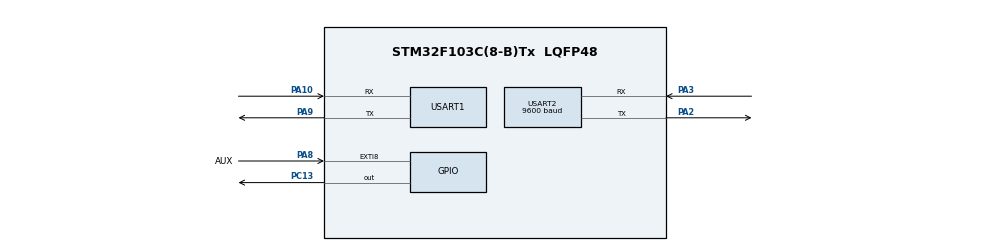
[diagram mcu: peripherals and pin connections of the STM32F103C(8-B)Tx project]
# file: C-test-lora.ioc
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Dma.Request0=USART2_RX
Dma.Request1=USART2_TX
Dma.USART2_RX.0.Direction=DMA_PERIPH_TO_MEMORY
Dma.USART2_RX.0.Instance=DMA1_Channel6
Dma.USART2_RX.0.MemDataAlignment=DMA_MDATAALIGN_BYTE
Dma.USART2_RX.0.MemInc=DMA_MINC_ENABLE
Dma.USART2_RX.0.Mode=DMA_NORMAL
Dma.USART2_RX.0.PeriphDataAlignment=DMA_PDATAALIGN_BYTE
Dma.USART2_RX.0.PeriphInc=DMA_PINC_DISABLE
Dma.USART2_RX.0.Priority=DMA_PRIORITY_LOW
Dma.USART2_TX.1.Direction=DMA_MEMORY_TO_PERIPH
Dma.USART2_TX.1.Instance=DMA1_Channel7
Dma.USART2_TX.1.MemDataAlignment=DMA_MDATAALIGN_BYTE
Dma.USART2_TX.1.MemInc=DMA_MINC_ENABLE
Dma.USART2_TX.1.Mode=DMA_NORMAL
Dma.USART2_TX.1.PeriphDataAlignment=DMA_PDATAALIGN_BYTE
Dma.USART2_TX.1.PeriphInc=DMA_PINC_DISABLE
Dma.USART2_TX.1.Priority=DMA_PRIORITY_LOW
FREERTOS.CountingSemaphores01=loraRxSem,10,Dynamic,NULL,0
FREERTOS.Queues01=loraErrQueue,16,lora_state_t,0,Dynamic,NULL,NULL;cmdQueue,16,uint8_t,0,Dynamic,NULL,NULL
FREERTOS.Tasks01=defaultTask,24,128,StartDefaultTask,Default,NULL,Dynamic,NULL,NULL;mainCmdTask,8,128,StartTaskMainCmd,As external,NULL,Dynamic,NULL,NULL
FREERTOS.configTOTAL_HEAP_SIZE=5000
Mcu.Family=STM32F1
Mcu.Name=STM32F103C(8-B)Tx
Mcu.Package=LQFP48
NVIC.DMA1_Channel6_IRQn=true\:5\:0\:false\:false\:true\:true\:false\:true\:true
NVIC.DMA1_Channel7_IRQn=true\:5\:0\:false\:false\:true\:true\:false\:true\:true
NVIC.EXTI9_5_IRQn=true\:5\:0\:false\:false\:true\:true\:true\:true\:true
NVIC.PriorityGroup=NVIC_PRIORITYGROUP_4
NVIC.TIM4_IRQn=true\:15\:0\:false\:false\:true\:false\:false\:true\:true
NVIC.TimeBase=TIM4_IRQn
NVIC.TimeBaseIP=TIM4
NVIC.USART2_IRQn=true\:5\:0\:false\:false\:true\:true\:false\:true\:true
PA10.Mode=Asynchronous
PA10.Signal=USART1_RX
PA13.Mode=Serial_Wire
PA13.Signal=SYS_JTMS-SWDIO
PA14.Mode=Serial_Wire
PA14.Signal=SYS_JTCK-SWCLK
PA2.Mode=Asynchronous
PA2.Signal=USART2_TX
PA3.Mode=Asynchronous
PA3.Signal=USART2_RX
PA8.GPIO_Label=AUX
PA8.GPIO_ModeDefaultEXTI=GPIO_MODE_IT_RISING
PA8.GPIO_PuPd=GPIO_PULLDOWN
PA8.Signal=GPXTI8
PA9.Mode=Asynchronous
PA9.Signal=USART1_TX
PC13-TAMPER-RTC.Signal=GPIO_Output
PD0-OSC_IN.Mode=HSE-External-Oscillator
PD0-OSC_IN.Signal=RCC_OSC_IN
PD1-OSC_OUT.Mode=HSE-External-Oscillator
PD1-OSC_OUT.Signal=RCC_OSC_OUT
ProjectManager.HeapSize=0x200
ProjectManager.StackSize=0x400
ProjectManager.TargetToolchain=STM32CubeIDE
RCC.APB1Freq_Value=8000000
RCC.APB2Freq_Value=8000000
USART1.VirtualMode=VM_ASYNC
USART2.BaudRate=9600
USART2.VirtualMode=VM_ASYNC
VP_FREERTOS_VS_CMSIS_V2.Mode=CMSIS_V2
VP_SYS_VS_tim4.Mode=TIM4
board=custom

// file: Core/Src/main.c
/* USER CODE BEGIN Header */
/**
  ******************************************************************************
  * @file           : main.c
  * @brief          : Main program body
  ******************************************************************************
  * @attention
  *
  * Copyright (c) 2026 STMicroelectronics.
  * All rights reserved.
  *
  * This software is licensed under terms that can be found in the LICENSE file
  * in the root directory of this software component.
  * If no LICENSE file comes with this software, it is provided AS-IS.
  *
  ******************************************************************************
  */
/* USER CODE END Header */
#include "main.h"
#include "cmsis_os.h"
#include "dma.h"
#include "usart.h"
#include "gpio.h"

/* USER CODE BEGIN Includes */
#include "lora.h"
/* USER CODE END Includes */

void SystemClock_Config(void);
void MX_FREERTOS_Init(void);

int main(void)
{

  /* MCU Configuration--------------------------------------------------------*/

  /* Reset of all peripherals, Initializes the Flash interface and the Systick. */
  HAL_Init();

  /* Configure the system clock */
  SystemClock_Config();

  /* Initialize all configured peripherals */
  MX_GPIO_Init();
  MX_DMA_Init();
  MX_USART2_UART_Init();
  MX_USART1_UART_Init();
  /* USER CODE BEGIN 2 */
  /* 板载 LED：多数 F103 小板是低电平点亮，这里拉高只是先把状态定下来 */
  HAL_GPIO_WritePin(GPIOC, GPIO_PIN_13, GPIO_PIN_SET);

  /* 配置 LoRa：进 AT -> 设参数 -> 复位 -> 挂接收，全程阻塞约 1.5 秒。
     必须在调度器启动前做，因为 lora_init 里用的是 HAL_Delay，不依赖 RTOS。 */
  lora_init();

  /* 自检：给对端发 5 字节，另一块板的串口助手应原样收到 "shabi" */
  lora_send((uint8_t *)"shabi", 5);

  /* USER CODE END 2 */

  /* Init scheduler */
  osKernelInitialize();  /* Call init function for freertos objects (in cmsis_os2.c) */
  MX_FREERTOS_Init();

  /* Start scheduler */
  osKernelStart();

  /* We should never get here as control is now taken by the scheduler */

  /* Infinite loop */
  while (1)
  {

  }
}

void SystemClock_Config(void)
{
  RCC_OscInitTypeDef RCC_OscInitStruct = {0};
  RCC_ClkInitTypeDef RCC_ClkInitStruct = {0};

  /** Initializes the RCC Oscillators according to the specified parameters
  * in the RCC_OscInitTypeDef structure.
  */
  RCC_OscInitStruct.OscillatorType = RCC_OSCILLATORTYPE_HSI;
  RCC_OscInitStruct.HSIState = RCC_HSI_ON;
  RCC_OscInitStruct.HSICalibrationValue = RCC_HSICALIBRATION_DEFAULT;
  RCC_OscInitStruct.PLL.PLLState = RCC_PLL_NONE;
  if (HAL_RCC_OscConfig(&RCC_OscInitStruct) != HAL_OK)
  {
    Error_Handler();
  }

  /** Initializes the CPU, AHB and APB buses clocks
  */
  RCC_ClkInitStruct.ClockType = RCC_CLOCKTYPE_HCLK|RCC_CLOCKTYPE_SYSCLK
                              |RCC_CLOCKTYPE_PCLK1|RCC_CLOCKTYPE_PCLK2;
  RCC_ClkInitStruct.SYSCLKSource = RCC_SYSCLKSOURCE_HSI;
  RCC_ClkInitStruct.AHBCLKDivider = RCC_SYSCLK_DIV1;
  RCC_ClkInitStruct.APB1CLKDivider = RCC_HCLK_DIV1;
  RCC_ClkInitStruct.APB2CLKDivider = RCC_HCLK_DIV1;

  if (HAL_RCC_ClockConfig(&RCC_ClkInitStruct, FLASH_LATENCY_0) != HAL_OK)
  {
    Error_Handler();
  }
}

void HAL_TIM_PeriodElapsedCallback(TIM_HandleTypeDef *htim)
{
  if (htim->Instance == TIM4)
  {
    HAL_IncTick();
  }
}

void Error_Handler(void)
{
  __disable_irq();
  while (1)
  {
  }
}

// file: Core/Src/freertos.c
/* USER CODE BEGIN Header */
/**
  ******************************************************************************
  * File Name          : freertos.c
  * Description        : Code for freertos applications
  ******************************************************************************
  * @attention
  *
  * Copyright (c) 2026 STMicroelectronics.
  * All rights reserved.
  *
  * This software is licensed under terms that can be found in the LICENSE file
  * in the root directory of this software component.
  * If no LICENSE file comes with this software, it is provided AS-IS.
  *
  ******************************************************************************
  */
/* USER CODE END Header */

#include "FreeRTOS.h"
#include "task.h"
#include "main.h"
#include "cmsis_os.h"

/* USER CODE BEGIN Includes */
#include "lora.h"
/* USER CODE END Includes */

/* Definitions for defaultTask */
osThreadId_t defaultTaskHandle;
const osThreadAttr_t defaultTask_attributes = {
  .name = "defaultTask",
  .stack_size = 128 * 4,
  .priority = (osPriority_t) osPriorityNormal,
};
/* Definitions for mainCmdTask */
osThreadId_t mainCmdTaskHandle;
const osThreadAttr_t mainCmdTask_attributes = {
  .name = "mainCmdTask",
  .stack_size = 128 * 4,
  .priority = (osPriority_t) osPriorityLow,
};
/* Definitions for loraErrQueue */
osMessageQueueId_t loraErrQueueHandle;
const osMessageQueueAttr_t loraErrQueue_attributes = {
  .name = "loraErrQueue"
};
/* Definitions for cmdQueue */
osMessageQueueId_t cmdQueueHandle;
const osMessageQueueAttr_t cmdQueue_attributes = {
  .name = "cmdQueue"
};
/* Definitions for loraRxSem */
osSemaphoreId_t loraRxSemHandle;
const osSemaphoreAttr_t loraRxSem_attributes = {
  .name = "loraRxSem"
};

void StartDefaultTask(void *argument);
extern void StartTaskMainCmd(void *argument);

void MX_FREERTOS_Init(void); /* (MISRA C 2004 rule 8.1) */

void MX_FREERTOS_Init(void) {

  /* Create the semaphores(s) */
  /* creation of loraRxSem */
  loraRxSemHandle = osSemaphoreNew(10, 0, &loraRxSem_attributes);

  /* Create the queue(s) */
  /* creation of loraErrQueue */
  loraErrQueueHandle = osMessageQueueNew (16, sizeof(lora_state_t), &loraErrQueue_attributes);

  /* creation of cmdQueue */
  cmdQueueHandle = osMessageQueueNew (16, sizeof(uint8_t), &cmdQueue_attributes);

  /* Create the thread(s) */
  /* creation of defaultTask */
  defaultTaskHandle = osThreadNew(StartDefaultTask, NULL, &defaultTask_attributes);

  /* creation of mainCmdTask */
  mainCmdTaskHandle = osThreadNew(StartTaskMainCmd, NULL, &mainCmdTask_attributes);

}

void StartDefaultTask(void *argument)
{
  for(;;)
  {
    osDelay(1);
  }
}
